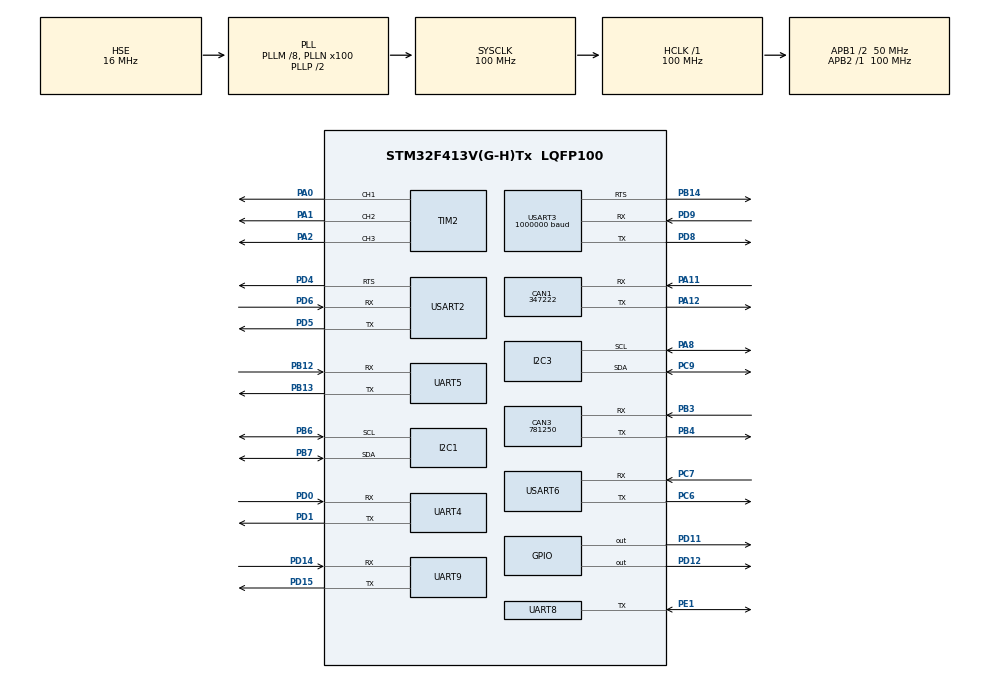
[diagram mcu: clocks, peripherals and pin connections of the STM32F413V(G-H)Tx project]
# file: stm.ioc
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CAN1.BS1=CAN_BS1_4TQ
CAN1.BS2=CAN_BS2_4TQ
CAN1.CalculateBaudRate=347222
CAN1.CalculateTimeBit=2880
CAN1.CalculateTimeQuantum=320.0
CAN3.BS1=CAN_BS1_2TQ
CAN3.CalculateBaudRate=781250
CAN3.CalculateTimeBit=1280
CAN3.CalculateTimeQuantum=320.0
Mcu.Family=STM32F4
Mcu.Name=STM32F413V(G-H)Tx
Mcu.Package=LQFP100
NVIC.PriorityGroup=NVIC_PRIORITYGROUP_4
PA0.Signal=S_TIM2_CH1_ETR
PA1.Signal=S_TIM2_CH2
PA11.Mode=CAN_Activate
PA11.Signal=CAN1_RX
PA12.Mode=CAN_Activate
PA12.Signal=CAN1_TX
PA13.Mode=Serial_Wire
PA13.Signal=SYS_JTMS-SWDIO
PA14.Mode=Serial_Wire
PA14.Signal=SYS_JTCK-SWCLK
PA2.Signal=S_TIM2_CH3
PA8.GPIO_Pu=GPIO_PULLUP
PA8.Mode=I2C
PA8.Signal=I2C3_SCL
PB12.Mode=Asynchronous
PB12.Signal=UART5_RX
PB13.Mode=Asynchronous
PB13.Signal=UART5_TX
PB14.Mode=RTS_Only
PB14.Signal=USART3_RTS
PB3.Mode=CAN_Activate
PB3.Signal=CAN3_RX
PB4.Mode=CAN_Activate
PB4.Signal=CAN3_TX
PB6.GPIO_Pu=GPIO_PULLUP
PB6.Mode=I2C
PB6.Signal=I2C1_SCL
PB7.GPIO_Pu=GPIO_PULLUP
PB7.Mode=I2C
PB7.Signal=I2C1_SDA
PC14-OSC32_IN.Mode=LSE-External-Oscillator
PC14-OSC32_IN.Signal=RCC_OSC32_IN
PC15-OSC32_OUT.Mode=LSE-External-Oscillator
PC15-OSC32_OUT.Signal=RCC_OSC32_OUT
PC6.Mode=Asynchronous
PC6.Signal=USART6_TX
PC7.Mode=Asynchronous
PC7.Signal=USART6_RX
PC9.GPIO_Pu=GPIO_PULLUP
PC9.Mode=I2C
PC9.Signal=I2C3_SDA
PD0.Mode=Asynchronous
PD0.Signal=UART4_RX
PD1.Mode=Asynchronous
PD1.Signal=UART4_TX
PD11.Signal=GPIO_Output
PD12.Signal=GPIO_Output
PD14.Mode=Asynchronous
PD14.Signal=UART9_RX
PD15.Mode=Asynchronous
PD15.Signal=UART9_TX
PD4.Mode=RTS_Only
PD4.Signal=USART2_RTS
PD5.Mode=Asynchronous
PD5.Signal=USART2_TX
PD6.Mode=Asynchronous
PD6.Signal=USART2_RX
PD8.Mode=Asynchronous
PD8.Signal=USART3_TX
PD9.Mode=Asynchronous
PD9.Signal=USART3_RX
PE1.Mode=Half_duplex(single_wire_mode)
PE1.Signal=UART8_TX
PH0\ -\ OSC_IN.Mode=HSE-External-Oscillator
PH0\ -\ OSC_IN.Signal=RCC_OSC_IN
PH1\ -\ OSC_OUT.Mode=HSE-External-Oscillator
PH1\ -\ OSC_OUT.Signal=RCC_OSC_OUT
ProjectManager.HeapSize=0x200
ProjectManager.StackSize=0x400
ProjectManager.TargetToolchain=STM32CubeIDE
RCC.AHBFreq_Value=100000000
RCC.APB1CLKDivider=RCC_HCLK_DIV2
RCC.APB1Freq_Value=50000000
RCC.APB1TimFreq_Value=100000000
RCC.APB2Freq_Value=100000000
RCC.APB2TimFreq_Value=100000000
RCC.CortexFreq_Value=100000000
RCC.HCLKFreq_Value=100000000
RCC.HSE_VALUE=16000000
RCC.PLLM=8
RCC.PLLN=100
RCC.PLLQ=4
RCC.PLLSourceVirtual=RCC_PLLSOURCE_HSE
RCC.RCC_RTC_Clock_Source=RCC_RTCCLKSOURCE_LSE
RCC.RCC_RTC_Clock_SourceVirtual=RCC_RTCCLKSOURCE_LSE
RCC.SYSCLKFreq_VALUE=100000000
RCC.SYSCLKSource=RCC_SYSCLKSOURCE_PLLCLK
RCC.USBFreq_Value=50000000
RCC.VCOOutputFreq_Value=200000000
SH.S_TIM2_CH1_ETR.0=TIM2_CH1,PWM Generation1 CH1
SH.S_TIM2_CH2.0=TIM2_CH2,PWM Generation2 CH2
SH.S_TIM2_CH3.0=TIM2_CH3,PWM Generation3 CH3
TIM2.Channel-PWM\ Generation1\ CH1=TIM_CHANNEL_1
TIM2.Channel-PWM\ Generation2\ CH2=TIM_CHANNEL_2
TIM2.Channel-PWM\ Generation3\ CH3=TIM_CHANNEL_3
UART4.VirtualMode=Asynchronous
UART5.VirtualMode=Asynchronous
UART8.VirtualMode=Asynchronous
UART9.VirtualMode=Asynchronous
USART2.Parity=PARITY_NONE
USART2.VirtualMode=VM_ASYNC
USART3.BaudRate=1000000
USART3.VirtualMode=VM_ASYNC
USART6.VirtualMode=VM_ASYNC
VP_RTC_VS_RTC_Activate.Mode=RTC_Enabled
VP_RTC_VS_RTC_Calendar.Mode=RTC_Calendar
board=custom

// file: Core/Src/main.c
/* USER CODE BEGIN Header */
/**
  ******************************************************************************
  * @file           : main.c
  * @brief          : Main program body
  ******************************************************************************
  * @attention
  *
  * Copyright (c) 2022 STMicroelectronics.
  * All rights reserved.
  *
  * This software is licensed under terms that can be found in the LICENSE file
  * in the root directory of this software component.
  * If no LICENSE file comes with this software, it is provided AS-IS.
  *
  ******************************************************************************
  */
/* USER CODE END Header */
#include "main.h"

/* USER CODE BEGIN Includes */
#include "kin_spp.h"
/* USER CODE END Includes */

CAN_HandleTypeDef hcan1;
CAN_HandleTypeDef hcan3;

I2C_HandleTypeDef hi2c1;
I2C_HandleTypeDef hi2c3;

RTC_HandleTypeDef hrtc;

TIM_HandleTypeDef htim2;

UART_HandleTypeDef huart4;
UART_HandleTypeDef huart5;
UART_HandleTypeDef huart8;
UART_HandleTypeDef huart9;
UART_HandleTypeDef huart2;
UART_HandleTypeDef huart3;
UART_HandleTypeDef huart6;

void SystemClock_Config(void);
static void MX_GPIO_Init(void);
static void MX_CAN1_Init(void);
static void MX_I2C1_Init(void);
static void MX_I2C3_Init(void);
static void MX_UART4_Init(void);
static void MX_USART2_UART_Init(void);
static void MX_USART3_UART_Init(void);
static void MX_RTC_Init(void);
static void MX_UART8_Init(void);
static void MX_UART9_Init(void);
static void MX_USART6_UART_Init(void);
static void MX_CAN3_Init(void);
static void MX_TIM2_Init(void);
static void MX_UART5_Init(void);

int main(void)
{

  /* MCU Configuration--------------------------------------------------------*/

  /* Reset of all peripherals, Initializes the Flash interface and the Systick. */
  HAL_Init();

  /* USER CODE BEGIN Init */

  spp_packet_t packet;
  spp_init_packet(&packet);

  uint8_t rx_buff[SPP_PACKET_LEN];
  uint8_t tx_buff[SPP_PACKET_LEN];

  uint8_t ping[4] = "ping";
  uint8_t pong[4] = "pong";

  /* USER CODE END Init */

  /* Configure the system clock */
  SystemClock_Config();

  /* Initialize all configured peripherals */
  MX_GPIO_Init();
  MX_CAN1_Init();
  MX_I2C1_Init();
  MX_I2C3_Init();
  MX_UART4_Init();
  MX_USART2_UART_Init();
  MX_USART3_UART_Init();
  MX_RTC_Init();
  MX_UART8_Init();
  MX_UART9_Init();
  MX_USART6_UART_Init();
  MX_CAN3_Init();
  MX_TIM2_Init();
  MX_UART5_Init();

  /* Infinite loop */
  while (1)
  {

	  if (HAL_UART_Receive(&huart6, rx_buff, SPP_PACKET_LEN, HAL_MAX_DELAY) == HAL_OK) {

		  spp_buffer_to_packet(&packet, rx_buff);

		  switch (packet.header.id.apid) {

			  case (SPP_APID_GS | SPP_APID_PING):

				  spp_set_header(&packet, SPP_VERSION_NUMBER, SPP_TYPE_TM, SPP_SEC_HDR_F_0, SPP_APID_CS | SPP_APID_PONG, SPP_SEQ_CTRL_F_US, 0);
				  spp_set_data(&packet, packet.header.data_len, pong);
				  spp_packet_to_buffer(&packet, tx_buff);

				  HAL_UART_Transmit(&huart6, tx_buff, packet.header.data_len+SPP_HEADER_LEN, HAL_MAX_DELAY);
				  break;

			  case (SPP_APID_GS | SPP_APID_PONG):

				  spp_set_header(&packet, SPP_VERSION_NUMBER, SPP_TYPE_TM, SPP_SEC_HDR_F_0, SPP_APID_CS | SPP_APID_PING, SPP_SEQ_CTRL_F_US, 0);
				  spp_set_data(&packet, packet.header.data_len, ping);
				  spp_packet_to_buffer(&packet, tx_buff);

				  HAL_UART_Transmit(&huart6, tx_buff, packet.header.data_len+SPP_HEADER_LEN, HAL_MAX_DELAY);
				  break;

		  }

	  }

  }
}

void SystemClock_Config(void)
{
  RCC_OscInitTypeDef RCC_OscInitStruct = {0};
  RCC_ClkInitTypeDef RCC_ClkInitStruct = {0};

  /** Configure the main internal regulator output voltage
  */
  __HAL_RCC_PWR_CLK_ENABLE();
  __HAL_PWR_VOLTAGESCALING_CONFIG(PWR_REGULATOR_VOLTAGE_SCALE1);

  /** Initializes the RCC Oscillators according to the specified parameters
  * in the RCC_OscInitTypeDef structure.
  */
  RCC_OscInitStruct.OscillatorType = RCC_OSCILLATORTYPE_HSE|RCC_OSCILLATORTYPE_LSE;
  RCC_OscInitStruct.HSEState = RCC_HSE_ON;
  RCC_OscInitStruct.LSEState = RCC_LSE_ON;
  RCC_OscInitStruct.PLL.PLLState = RCC_PLL_ON;
  RCC_OscInitStruct.PLL.PLLSource = RCC_PLLSOURCE_HSE;
  RCC_OscInitStruct.PLL.PLLM = 8;
  RCC_OscInitStruct.PLL.PLLN = 100;
  RCC_OscInitStruct.PLL.PLLP = RCC_PLLP_DIV2;
  RCC_OscInitStruct.PLL.PLLQ = 4;
  RCC_OscInitStruct.PLL.PLLR = 2;
  if (HAL_RCC_OscConfig(&RCC_OscInitStruct) != HAL_OK)
  {
    Error_Handler();
  }

  /** Initializes the CPU, AHB and APB buses clocks
  */
  RCC_ClkInitStruct.ClockType = RCC_CLOCKTYPE_HCLK|RCC_CLOCKTYPE_SYSCLK
                              |RCC_CLOCKTYPE_PCLK1|RCC_CLOCKTYPE_PCLK2;
  RCC_ClkInitStruct.SYSCLKSource = RCC_SYSCLKSOURCE_PLLCLK;
  RCC_ClkInitStruct.AHBCLKDivider = RCC_SYSCLK_DIV1;
  RCC_ClkInitStruct.APB1CLKDivider = RCC_HCLK_DIV2;
  RCC_ClkInitStruct.APB2CLKDivider = RCC_HCLK_DIV1;

  if (HAL_RCC_ClockConfig(&RCC_ClkInitStruct, FLASH_LATENCY_3) != HAL_OK)
  {
    Error_Handler();
  }
}

static void MX_CAN1_Init(void)
{

  hcan1.Instance = CAN1;
  hcan1.Init.Prescaler = 16;
  hcan1.Init.Mode = CAN_MODE_NORMAL;
  hcan1.Init.SyncJumpWidth = CAN_SJW_1TQ;
  hcan1.Init.TimeSeg1 = CAN_BS1_4TQ;
  hcan1.Init.TimeSeg2 = CAN_BS2_4TQ;
  hcan1.Init.TimeTriggeredMode = DISABLE;
  hcan1.Init.AutoBusOff = DISABLE;
  hcan1.Init.AutoWakeUp = DISABLE;
  hcan1.Init.AutoRetransmission = DISABLE;
  hcan1.Init.ReceiveFifoLocked = DISABLE;
  hcan1.Init.TransmitFifoPriority = DISABLE;
  if (HAL_CAN_Init(&hcan1) != HAL_OK)
  {
    Error_Handler();
  }

}

static void MX_CAN3_Init(void)
{

  hcan3.Instance = CAN3;
  hcan3.Init.Prescaler = 16;
  hcan3.Init.Mode = CAN_MODE_NORMAL;
  hcan3.Init.SyncJumpWidth = CAN_SJW_1TQ;
  hcan3.Init.TimeSeg1 = CAN_BS1_2TQ;
  hcan3.Init.TimeSeg2 = CAN_BS2_1TQ;
  hcan3.Init.TimeTriggeredMode = DISABLE;
  hcan3.Init.AutoBusOff = DISABLE;
  hcan3.Init.AutoWakeUp = DISABLE;
  hcan3.Init.AutoRetransmission = DISABLE;
  hcan3.Init.ReceiveFifoLocked = DISABLE;
  hcan3.Init.TransmitFifoPriority = DISABLE;
  if (HAL_CAN_Init(&hcan3) != HAL_OK)
  {
    Error_Handler();
  }

}

static void MX_I2C1_Init(void)
{

  hi2c1.Instance = I2C1;
  hi2c1.Init.ClockSpeed = 100000;
  hi2c1.Init.DutyCycle = I2C_DUTYCYCLE_2;
  hi2c1.Init.OwnAddress1 = 0;
  hi2c1.Init.AddressingMode = I2C_ADDRESSINGMODE_7BIT;
  hi2c1.Init.DualAddressMode = I2C_DUALADDRESS_DISABLE;
  hi2c1.Init.OwnAddress2 = 0;
  hi2c1.Init.GeneralCallMode = I2C_GENERALCALL_DISABLE;
  hi2c1.Init.NoStretchMode = I2C_NOSTRETCH_DISABLE;
  if (HAL_I2C_Init(&hi2c1) != HAL_OK)
  {
    Error_Handler();
  }

}

static void MX_I2C3_Init(void)
{

  hi2c3.Instance = I2C3;
  hi2c3.Init.ClockSpeed = 100000;
  hi2c3.Init.DutyCycle = I2C_DUTYCYCLE_2;
  hi2c3.Init.OwnAddress1 = 0;
  hi2c3.Init.AddressingMode = I2C_ADDRESSINGMODE_7BIT;
  hi2c3.Init.DualAddressMode = I2C_DUALADDRESS_DISABLE;
  hi2c3.Init.OwnAddress2 = 0;
  hi2c3.Init.GeneralCallMode = I2C_GENERALCALL_DISABLE;
  hi2c3.Init.NoStretchMode = I2C_NOSTRETCH_DISABLE;
  if (HAL_I2C_Init(&hi2c3) != HAL_OK)
  {
    Error_Handler();
  }

}

static void MX_RTC_Init(void)
{

  RTC_TimeTypeDef sTime = {0};
  RTC_DateTypeDef sDate = {0};

  /** Initialize RTC Only
  */
  hrtc.Instance = RTC;
  hrtc.Init.HourFormat = RTC_HOURFORMAT_24;
  hrtc.Init.AsynchPrediv = 127;
  hrtc.Init.SynchPrediv = 255;
  hrtc.Init.OutPut = RTC_OUTPUT_DISABLE;
  hrtc.Init.OutPutPolarity = RTC_OUTPUT_POLARITY_HIGH;
  hrtc.Init.OutPutType = RTC_OUTPUT_TYPE_OPENDRAIN;
  if (HAL_RTC_Init(&hrtc) != HAL_OK)
  {
    Error_Handler();
  }

  /** Initialize RTC and set the Time and Date
  */
  sTime.Hours = 0x0;
  sTime.Minutes = 0x0;
  sTime.Seconds = 0x0;
  sTime.DayLightSaving = RTC_DAYLIGHTSAVING_NONE;
  sTime.StoreOperation = RTC_STOREOPERATION_RESET;
  if (HAL_RTC_SetTime(&hrtc, &sTime, RTC_FORMAT_BCD) != HAL_OK)
  {
    Error_Handler();
  }
  sDate.WeekDay = RTC_WEEKDAY_MONDAY;
  sDate.Month = RTC_MONTH_JANUARY;
  sDate.Date = 0x1;
  sDate.Year = 0x0;

  if (HAL_RTC_SetDate(&hrtc, &sDate, RTC_FORMAT_BCD) != HAL_OK)
  {
    Error_Handler();
  }

}

static void MX_TIM2_Init(void)
{

  TIM_MasterConfigTypeDef sMasterConfig = {0};
  TIM_OC_InitTypeDef sConfigOC = {0};

  htim2.Instance = TIM2;
  htim2.Init.Prescaler = 0;
  htim2.Init.CounterMode = TIM_COUNTERMODE_UP;
  htim2.Init.Period = 4294967295;
  htim2.Init.ClockDivision = TIM_CLOCKDIVISION_DIV1;
  htim2.Init.AutoReloadPreload = TIM_AUTORELOAD_PRELOAD_DISABLE;
  if (HAL_TIM_PWM_Init(&htim2) != HAL_OK)
  {
    Error_Handler();
  }
  sMasterConfig.MasterOutputTrigger = TIM_TRGO_RESET;
  sMasterConfig.MasterSlaveMode = TIM_MASTERSLAVEMODE_DISABLE;
  if (HAL_TIMEx_MasterConfigSynchronization(&htim2, &sMasterConfig) != HAL_OK)
  {
    Error_Handler();
  }
  sConfigOC.OCMode = TIM_OCMODE_PWM1;
  sConfigOC.Pulse = 0;
  sConfigOC.OCPolarity = TIM_OCPOLARITY_HIGH;
  sConfigOC.OCFastMode = TIM_OCFAST_DISABLE;
  if (HAL_TIM_PWM_ConfigChannel(&htim2, &sConfigOC, TIM_CHANNEL_1) != HAL_OK)
  {
    Error_Handler();
  }
  if (HAL_TIM_PWM_ConfigChannel(&htim2, &sConfigOC, TIM_CHANNEL_2) != HAL_OK)
  {
    Error_Handler();
  }
  if (HAL_TIM_PWM_ConfigChannel(&htim2, &sConfigOC, TIM_CHANNEL_3) != HAL_OK)
  {
    Error_Handler();
  }
  HAL_TIM_MspPostInit(&htim2);

}

static void MX_UART4_Init(void)
{

  huart4.Instance = UART4;
  huart4.Init.BaudRate = 115200;
  huart4.Init.WordLength = UART_WORDLENGTH_8B;
  huart4.Init.StopBits = UART_STOPBITS_1;
  huart4.Init.Parity = UART_PARITY_NONE;
  huart4.Init.Mode = UART_MODE_TX_RX;
  huart4.Init.HwFlowCtl = UART_HWCONTROL_NONE;
  huart4.Init.OverSampling = UART_OVERSAMPLING_16;
  if (HAL_UART_Init(&huart4) != HAL_OK)
  {
    Error_Handler();
  }

}

static void MX_UART5_Init(void)
{

  huart5.Instance = UART5;
  huart5.Init.BaudRate = 115200;
  huart5.Init.WordLength = UART_WORDLENGTH_8B;
  huart5.Init.StopBits = UART_STOPBITS_1;
  huart5.Init.Parity = UART_PARITY_NONE;
  huart5.Init.Mode = UART_MODE_TX_RX;
  huart5.Init.HwFlowCtl = UART_HWCONTROL_NONE;
  huart5.Init.OverSampling = UART_OVERSAMPLING_16;
  if (HAL_UART_Init(&huart5) != HAL_OK)
  {
    Error_Handler();
  }

}

static void MX_UART8_Init(void)
{

  huart8.Instance = UART8;
  huart8.Init.BaudRate = 115200;
  huart8.Init.WordLength = UART_WORDLENGTH_8B;
  huart8.Init.StopBits = UART_STOPBITS_1;
  huart8.Init.Parity = UART_PARITY_NONE;
  huart8.Init.Mode = UART_MODE_TX_RX;
  huart8.Init.HwFlowCtl = UART_HWCONTROL_NONE;
  huart8.Init.OverSampling = UART_OVERSAMPLING_16;
  if (HAL_HalfDuplex_Init(&huart8) != HAL_OK)
  {
    Error_Handler();
  }

}

static void MX_UART9_Init(void)
{

  huart9.Instance = UART9;
  huart9.Init.BaudRate = 115200;
  huart9.Init.WordLength = UART_WORDLENGTH_8B;
  huart9.Init.StopBits = UART_STOPBITS_1;
  huart9.Init.Parity = UART_PARITY_NONE;
  huart9.Init.Mode = UART_MODE_TX_RX;
  huart9.Init.HwFlowCtl = UART_HWCONTROL_NONE;
  huart9.Init.OverSampling = UART_OVERSAMPLING_16;
  if (HAL_UART_Init(&huart9) != HAL_OK)
  {
    Error_Handler();
  }

}

static void MX_USART2_UART_Init(void)
{

  huart2.Instance = USART2;
  huart2.Init.BaudRate = 115200;
  huart2.Init.WordLength = UART_WORDLENGTH_8B;
  huart2.Init.StopBits = UART_STOPBITS_1;
  huart2.Init.Parity = UART_PARITY_NONE;
  huart2.Init.Mode = UART_MODE_TX_RX;
  huart2.Init.HwFlowCtl = UART_HWCONTROL_RTS;
  huart2.Init.OverSampling = UART_OVERSAMPLING_16;
  if (HAL_UART_Init(&huart2) != HAL_OK)
  {
    Error_Handler();
  }

}

static void MX_USART3_UART_Init(void)
{

  huart3.Instance = USART3;
  huart3.Init.BaudRate = 1000000;
  huart3.Init.WordLength = UART_WORDLENGTH_8B;
  huart3.Init.StopBits = UART_STOPBITS_1;
  huart3.Init.Parity = UART_PARITY_NONE;
  huart3.Init.Mode = UART_MODE_TX_RX;
  huart3.Init.HwFlowCtl = UART_HWCONTROL_RTS;
  huart3.Init.OverSampling = UART_OVERSAMPLING_16;
  if (HAL_UART_Init(&huart3) != HAL_OK)
  {
    Error_Handler();
  }

}

static void MX_USART6_UART_Init(void)
{

  huart6.Instance = USART6;
  huart6.Init.BaudRate = 115200;
  huart6.Init.WordLength = UART_WORDLENGTH_8B;
  huart6.Init.StopBits = UART_STOPBITS_1;
  huart6.Init.Parity = UART_PARITY_NONE;
  huart6.Init.Mode = UART_MODE_TX_RX;
  huart6.Init.HwFlowCtl = UART_HWCONTROL_NONE;
  huart6.Init.OverSampling = UART_OVERSAMPLING_16;
  if (HAL_UART_Init(&huart6) != HAL_OK)
  {
    Error_Handler();
  }

}

static void MX_GPIO_Init(void)
{
  GPIO_InitTypeDef GPIO_InitStruct = {0};

  /* GPIO Ports Clock Enable */
  __HAL_RCC_GPIOC_CLK_ENABLE();
  __HAL_RCC_GPIOH_CLK_ENABLE();
  __HAL_RCC_GPIOA_CLK_ENABLE();
  __HAL_RCC_GPIOB_CLK_ENABLE();
  __HAL_RCC_GPIOD_CLK_ENABLE();
  __HAL_RCC_GPIOE_CLK_ENABLE();

  /*Configure GPIO pin Output Level */
  HAL_GPIO_WritePin(GPIOD, GPIO_PIN_11|GPIO_PIN_12, GPIO_PIN_RESET);

  /*Configure GPIO pins : PD11 PD12 */
  GPIO_InitStruct.Pin = GPIO_PIN_11|GPIO_PIN_12;
  GPIO_InitStruct.Mode = GPIO_MODE_OUTPUT_PP;
  GPIO_InitStruct.Pull = GPIO_NOPULL;
  GPIO_InitStruct.Speed = GPIO_SPEED_FREQ_LOW;
  HAL_GPIO_Init(GPIOD, &GPIO_InitStruct);

}

void Error_Handler(void)
{
  __disable_irq();
  while (1)
  {
  }
}
